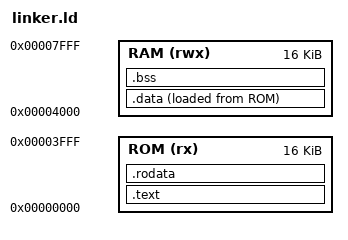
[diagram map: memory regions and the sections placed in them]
OUTPUT_ARCH(riscv)
ENTRY(_start)

MEMORY {
    ROM (rx)  : ORIGIN = 0x00000000, LENGTH = 16K
    RAM (rwx) : ORIGIN = 0x00004000, LENGTH = 16K
}

SECTIONS {
    .text : {
        *(.text.startup)
        *(.text)
        *(.text.*)
    } > ROM

    .rodata : {
        *(.rodata)
        *(.rodata.*)
    } > ROM

    .data : {
        _data_start = .;
        *(.data)
        *(.data.*)
        _data_end = .;
    } > RAM AT > ROM

    _data_load = LOADADDR(.data);

    .bss : {
        _bss_start = .;
        *(.bss)
        *(.bss.*)
        _bss_end = .;
    } > RAM

    _stack_top = ORIGIN(RAM) + LENGTH(RAM);
}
